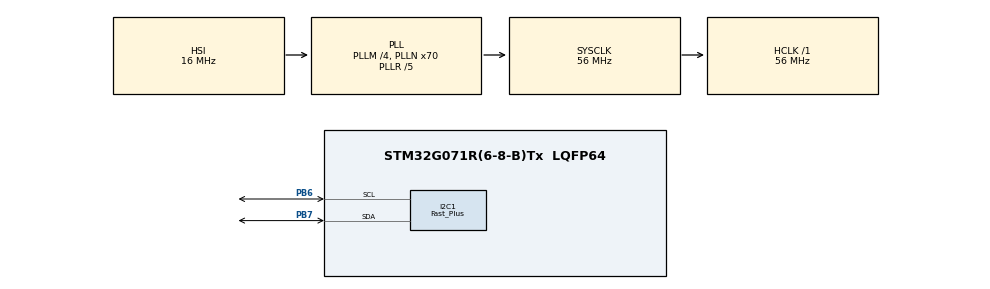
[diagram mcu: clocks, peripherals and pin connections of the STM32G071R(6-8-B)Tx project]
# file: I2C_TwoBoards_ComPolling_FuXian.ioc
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I2C1.AddressingMode=I2C_ADDRESSINGMODE_10BIT
I2C1.I2C_Fall_Time=2
I2C1.I2C_Rise_Time=26
I2C1.I2C_Speed_Mode=I2C_Fast_Plus
I2C1.OwnAddress=I2C_ADDRESS
I2C1.Timing=0x00400922
Mcu.Family=STM32G0
Mcu.Name=STM32G071R(6-8-B)Tx
Mcu.Package=LQFP64
Mcu.UserConstants=I2C_ADDRESS,0x30F
PB6.Mode=I2C
PB6.Signal=I2C1_SCL
PB7.Mode=I2C
PB7.Signal=I2C1_SDA
ProjectManager.HeapSize=0x200
ProjectManager.StackSize=0x400
ProjectManager.TargetToolchain=MDK-ARM V5.27
RCC.ADCFreq_Value=56000000
RCC.AHBFreq_Value=56000000
RCC.CodegenConfigPeriph=false
RCC.CortexFreq_Value=56000000
RCC.EXTERNAL_CLOCK_VALUE=48000
RCC.HCLKFreq_Value=56000000
RCC.HSE_VALUE=8000000
RCC.HSI_VALUE=16000000
RCC.LSE_VALUE=32768
RCC.PLLM=RCC_PLLM_DIV4
RCC.PLLN=70
RCC.PLLP=RCC_PLLP_DIV10
RCC.PLLQ=RCC_PLLQ_DIV5
RCC.PLLR=RCC_PLLR_DIV5
RCC.SYSCLKFreq_VALUE=56000000
RCC.SYSCLKSource=RCC_SYSCLKSOURCE_PLLCLK
RCC.VCOOutputFreq_Value=280000000
VP_SYS_VS_DBSignals.Mode=DisableDeadBatterySignals
board=custom

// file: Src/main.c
/*
	SCL Pin: PB6 (CN10, pin24)
	SDA Pin: PB7 (CN7, pin21)
 */

#include "main.h"
I2C_HandleTypeDef hi2c1;
void SystemClock_Config(void);
static void MX_GPIO_Init(void);
static void MX_I2C1_Init(void);

//#define MASTER_BOARD
#define TXBUFFERSIZE   162           //(COUNTOF(aTxBuffer) - 1)
#define RXBUFFERSIZE   TXBUFFERSIZE
uint8_t aTxBuffer[] = " ****I2C_TwoBoards communication based on Polling****  ****I2C_TwoBoards communication based on Polling****  ****I2C_TwoBoards communication based on Polling**** ";
uint8_t aRxBuffer[RXBUFFERSIZE];
static uint16_t Buffercmp(uint8_t *pBuffer1, uint8_t *pBuffer2, uint16_t BufferLength);

int main(void)
{
  HAL_Init();
  SystemClock_Config();
  MX_GPIO_Init();
  MX_I2C1_Init();

#ifdef MASTER_BOARD

/*  此段为测试代码，正式运行可删除
	while(1)
	{
		HAL_I2C_Master_Transmit(&hi2c1, (uint16_t)I2C_ADDRESS, (uint8_t *)aTxBuffer, 5, 10000);
		HAL_Delay(10);
	}
*/

  /* 主板通过发射缓存区发送数据，限时10S */
  while (HAL_I2C_Master_Transmit(&hi2c1, (uint16_t)I2C_ADDRESS, (uint8_t *)aTxBuffer, TXBUFFERSIZE, 10000) != HAL_OK)
  {
    /* 当Timeout错误发生时，调用Error_Handler()函数。
		当确认失败发生(从属服务器不确认其地址)时，主服务器重新启动通信		*/
    if (HAL_I2C_GetError(&hi2c1) != HAL_I2C_ERROR_AF)
      Error_Handler();
  }

  /* 进入接收模式等待数据传入，接收数据限时10S */
  while (HAL_I2C_Master_Receive(&hi2c1, (uint16_t)I2C_ADDRESS, (uint8_t *)aRxBuffer, RXBUFFERSIZE, 10000) != HAL_OK)
  {
    /* 当Timeout错误发生时，调用Error_Handler()函数。
		当确认失败发生(从属服务器不确认其地址)时，主服务器重新启动通信		*/
    if (HAL_I2C_GetError(&hi2c1) != HAL_I2C_ERROR_AF)
      Error_Handler();
  }

#else

  /* 从板接收数据并将其发回 */

  /*从板接收数据限时10S  */
/*	此段为测试代码，正式运行可删除
	while(1)
	{
		HAL_I2C_Slave_Receive(&hi2c1, (uint8_t *)aRxBuffer, 5, 10000);
		HAL_Delay(10);
	}
*/

  if (HAL_I2C_Slave_Receive(&hi2c1, (uint8_t *)aRxBuffer, RXBUFFERSIZE, 10000) != HAL_OK)
    Error_Handler();

  /* 从板利用发送缓冲区发送数据，限时10S */
  if (HAL_I2C_Slave_Transmit(&hi2c1, (uint8_t *)aTxBuffer, TXBUFFERSIZE, 10000) != HAL_OK)
    Error_Handler();

#endif

  /* 比较发送缓冲区与接收缓冲区，不同则警报 */
  if (Buffercmp((uint8_t *)aTxBuffer, (uint8_t *)aRxBuffer, RXBUFFERSIZE))
    Error_Handler();

  while (1)
  {
  }
}

void SystemClock_Config(void)
{
  RCC_OscInitTypeDef RCC_OscInitStruct = {0};
  RCC_ClkInitTypeDef RCC_ClkInitStruct = {0};

  /** Initializes the RCC Oscillators according to the specified parameters
  * in the RCC_OscInitTypeDef structure.
  */
  RCC_OscInitStruct.OscillatorType = RCC_OSCILLATORTYPE_HSI;
  RCC_OscInitStruct.HSIState = RCC_HSI_ON;
  RCC_OscInitStruct.HSIDiv = RCC_HSI_DIV1;
  RCC_OscInitStruct.HSICalibrationValue = RCC_HSICALIBRATION_DEFAULT;
  RCC_OscInitStruct.PLL.PLLState = RCC_PLL_ON;
  RCC_OscInitStruct.PLL.PLLSource = RCC_PLLSOURCE_HSI;
  RCC_OscInitStruct.PLL.PLLM = RCC_PLLM_DIV4;
  RCC_OscInitStruct.PLL.PLLN = 70;
  RCC_OscInitStruct.PLL.PLLP = RCC_PLLP_DIV10;
  RCC_OscInitStruct.PLL.PLLQ = RCC_PLLQ_DIV5;
  RCC_OscInitStruct.PLL.PLLR = RCC_PLLR_DIV5;
  if (HAL_RCC_OscConfig(&RCC_OscInitStruct) != HAL_OK)
  {
    Error_Handler();
  }
  /** Initializes the CPU, AHB and APB buses clocks
  */
  RCC_ClkInitStruct.ClockType = RCC_CLOCKTYPE_HCLK|RCC_CLOCKTYPE_SYSCLK
                              |RCC_CLOCKTYPE_PCLK1;
  RCC_ClkInitStruct.SYSCLKSource = RCC_SYSCLKSOURCE_PLLCLK;
  RCC_ClkInitStruct.AHBCLKDivider = RCC_SYSCLK_DIV1;
  RCC_ClkInitStruct.APB1CLKDivider = RCC_HCLK_DIV1;

  if (HAL_RCC_ClockConfig(&RCC_ClkInitStruct, FLASH_LATENCY_2) != HAL_OK)
  {
    Error_Handler();
  }
}

static void MX_I2C1_Init(void)
{

  hi2c1.Instance = I2C1;
  hi2c1.Init.Timing = 0x00400922;
  hi2c1.Init.OwnAddress1 = 783;
  hi2c1.Init.AddressingMode = I2C_ADDRESSINGMODE_10BIT;
  hi2c1.Init.DualAddressMode = I2C_DUALADDRESS_DISABLE;
  hi2c1.Init.OwnAddress2 = 0;
  hi2c1.Init.OwnAddress2Masks = I2C_OA2_NOMASK;
  hi2c1.Init.GeneralCallMode = I2C_GENERALCALL_DISABLE;
  hi2c1.Init.NoStretchMode = I2C_NOSTRETCH_DISABLE;
  if (HAL_I2C_Init(&hi2c1) != HAL_OK)
  {
    Error_Handler();
  }
  /** Configure Analogue filter
  */
  if (HAL_I2CEx_ConfigAnalogFilter(&hi2c1, I2C_ANALOGFILTER_ENABLE) != HAL_OK)
  {
    Error_Handler();
  }
  /** Configure Digital filter
  */
  if (HAL_I2CEx_ConfigDigitalFilter(&hi2c1, 0) != HAL_OK)
  {
    Error_Handler();
  }
  /** I2C Fast mode Plus enable
  */
  HAL_I2CEx_EnableFastModePlus(I2C_FASTMODEPLUS_I2C1);

}

static void MX_GPIO_Init(void)
{

  /* GPIO Ports Clock Enable */
  __HAL_RCC_GPIOB_CLK_ENABLE();

}

/* USER CODE BEGIN 4 */
static uint16_t Buffercmp(uint8_t *pBuffer1, uint8_t *pBuffer2, uint16_t BufferLength)
{
  while (BufferLength--)
  {
    if ((*pBuffer1) != *pBuffer2)
      return BufferLength;
    pBuffer1++;
    pBuffer2++;
  }
  return 0;
}
/* USER CODE END 4 */

void Error_Handler(void)
{
  __disable_irq();
  while (1)
  {
  }
}
